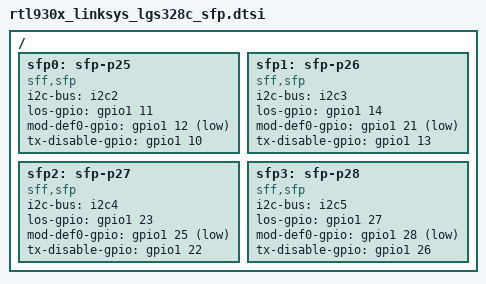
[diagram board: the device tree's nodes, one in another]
// SPDX-License-Identifier: (GPL-2.0-or-later or MIT)

/ {
	sfp0: sfp-p25 {
		compatible = "sff,sfp";
		i2c-bus = <&i2c2>;
		los-gpio = <&gpio1 11 GPIO_ACTIVE_HIGH>;
		mod-def0-gpio = <&gpio1 12 GPIO_ACTIVE_LOW>;
		tx-disable-gpio = <&gpio1 10 GPIO_ACTIVE_HIGH>;
	};
	sfp1: sfp-p26 {
		compatible = "sff,sfp";
		i2c-bus = <&i2c3>;
		los-gpio = <&gpio1 14 GPIO_ACTIVE_HIGH>;
		mod-def0-gpio = <&gpio1 21 GPIO_ACTIVE_LOW>;
		tx-disable-gpio = <&gpio1 13 GPIO_ACTIVE_HIGH>;
	};
	sfp2: sfp-p27 {
		compatible = "sff,sfp";
		i2c-bus = <&i2c4>;
		los-gpio = <&gpio1 23 GPIO_ACTIVE_HIGH>;
		mod-def0-gpio = <&gpio1 25 GPIO_ACTIVE_LOW>;
		tx-disable-gpio = <&gpio1 22 GPIO_ACTIVE_HIGH>;
	};
	sfp3: sfp-p28 {
		compatible = "sff,sfp";
		i2c-bus = <&i2c5>;
		los-gpio = <&gpio1 27 GPIO_ACTIVE_HIGH>;
		mod-def0-gpio = <&gpio1 28 GPIO_ACTIVE_LOW>;
		tx-disable-gpio = <&gpio1 26 GPIO_ACTIVE_HIGH>;
	};
};
